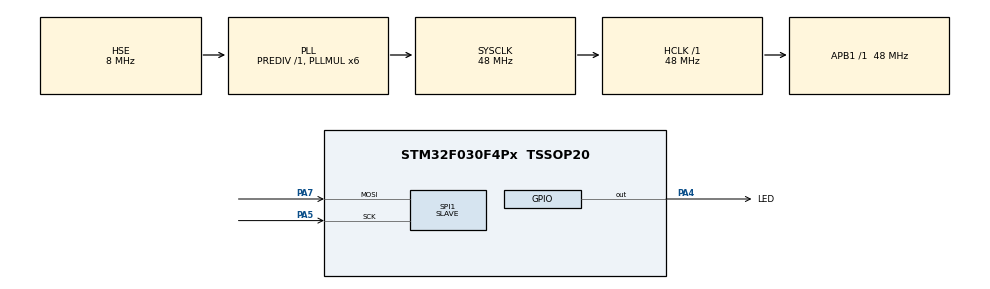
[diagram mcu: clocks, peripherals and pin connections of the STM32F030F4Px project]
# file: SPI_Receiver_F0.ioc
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Mcu.Family=STM32F0
Mcu.Name=STM32F030F4Px
Mcu.Package=TSSOP20
NVIC.SPI1_IRQn=true\:0\:0\:false\:false\:true\:true\:true
PA13.Mode=Serial_Wire
PA13.Signal=SYS_SWDIO
PA14.Mode=Serial_Wire
PA14.Signal=SYS_SWCLK
PA4.GPIO_Label=LED
PA4.Signal=GPIO_Output
PA5.Mode=RX_Only_Simplex_Unidirect_Slave
PA5.Signal=SPI1_SCK
PA7.Mode=RX_Only_Simplex_Unidirect_Slave
PA7.Signal=SPI1_MOSI
PF0-OSC_IN.Mode=HSE-External-Oscillator
PF0-OSC_IN.Signal=RCC_OSC_IN
PF1-OSC_OUT.Mode=HSE-External-Oscillator
PF1-OSC_OUT.Signal=RCC_OSC_OUT
ProjectManager.HeapSize=0x200
ProjectManager.StackSize=0x400
ProjectManager.TargetToolchain=STM32CubeIDE
RCC.AHBFreq_Value=48000000
RCC.APB1Freq_Value=48000000
RCC.APB1TimFreq_Value=48000000
RCC.HCLKFreq_Value=48000000
RCC.PLLMUL=RCC_PLL_MUL6
RCC.PLLSourceVirtual=RCC_PLLSOURCE_HSE
RCC.SYSCLKFreq_VALUE=48000000
RCC.SYSCLKSource=RCC_SYSCLKSOURCE_PLLCLK
SPI1.DataSize=SPI_DATASIZE_8BIT
SPI1.Direction=SPI_DIRECTION_2LINES_RXONLY
SPI1.Mode=SPI_MODE_SLAVE
SPI1.VirtualType=VM_SLAVE
board=custom

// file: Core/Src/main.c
/* USER CODE BEGIN Header */
/**
  ******************************************************************************
  * @file           : main.c
  * @brief          : Main program body
  ******************************************************************************
  * @attention
  *
  * <h2><center>&copy; Copyright (c) 2021 STMicroelectronics.
  * All rights reserved.</center></h2>
  *
  * This software component is licensed by ST under BSD 3-Clause license,
  * the "License"; You may not use this file except in compliance with the
  * License. You may obtain a copy of the License at:
  *                        opensource.org/licenses/BSD-3-Clause
  *
  ******************************************************************************
  */
/* USER CODE END Header */
#include "main.h"

SPI_HandleTypeDef hspi1;

void SystemClock_Config(void);
static void MX_GPIO_Init(void);
static void MX_SPI1_Init(void);

/* USER CODE BEGIN 0 */
void led_on()
{
  HAL_GPIO_WritePin(LED_GPIO_Port, LED_Pin, GPIO_PIN_RESET);
}

void led_off()
{
  HAL_GPIO_WritePin(LED_GPIO_Port, LED_Pin, GPIO_PIN_SET);
}

void led_toggle()
{
  HAL_GPIO_TogglePin(LED_GPIO_Port, LED_Pin);
}

long int count = 0;

void HAL_SPI_RxCpltCallback(SPI_HandleTypeDef *hspi)
{
  if(hspi == &hspi1)
  {
    // if(!hspi1.TxXferCount && !fl)
    // {
    //   fl=1;
    // }
//    led_toggle();
//    count++;
  }
  count++;
//  led_on();
  led_toggle();
}
/* USER CODE END 0 */

int main(void)
{

  /* MCU Configuration--------------------------------------------------------*/

  /* Reset of all peripherals, Initializes the Flash interface and the Systick. */
  HAL_Init();

  /* Configure the system clock */
  SystemClock_Config();

  /* Initialize all configured peripherals */
  MX_GPIO_Init();
  MX_SPI1_Init();
  /* USER CODE BEGIN 2 */
  led_on();
  HAL_Delay(2000);
  led_off();
  HAL_Delay(1000);

  uint8_t data_rx = 0;

  HAL_SPI_Receive_IT(&hspi1, &data_rx, sizeof(data_rx));
  /* USER CODE END 2 */

  /* Infinite loop */
  /* USER CODE BEGIN WHILE */
  while (1)
  {
	  HAL_Delay(5000);

	  HAL_Delay(1);
    /* USER CODE END WHILE */

  }
}

void SystemClock_Config(void)
{
  RCC_OscInitTypeDef RCC_OscInitStruct = {0};
  RCC_ClkInitTypeDef RCC_ClkInitStruct = {0};

  /** Initializes the RCC Oscillators according to the specified parameters
  * in the RCC_OscInitTypeDef structure.
  */
  RCC_OscInitStruct.OscillatorType = RCC_OSCILLATORTYPE_HSE;
  RCC_OscInitStruct.HSEState = RCC_HSE_ON;
  RCC_OscInitStruct.PLL.PLLState = RCC_PLL_ON;
  RCC_OscInitStruct.PLL.PLLSource = RCC_PLLSOURCE_HSE;
  RCC_OscInitStruct.PLL.PLLMUL = RCC_PLL_MUL6;
  RCC_OscInitStruct.PLL.PREDIV = RCC_PREDIV_DIV1;
  if (HAL_RCC_OscConfig(&RCC_OscInitStruct) != HAL_OK)
  {
    Error_Handler();
  }
  /** Initializes the CPU, AHB and APB buses clocks
  */
  RCC_ClkInitStruct.ClockType = RCC_CLOCKTYPE_HCLK|RCC_CLOCKTYPE_SYSCLK
                              |RCC_CLOCKTYPE_PCLK1;
  RCC_ClkInitStruct.SYSCLKSource = RCC_SYSCLKSOURCE_PLLCLK;
  RCC_ClkInitStruct.AHBCLKDivider = RCC_SYSCLK_DIV1;
  RCC_ClkInitStruct.APB1CLKDivider = RCC_HCLK_DIV1;

  if (HAL_RCC_ClockConfig(&RCC_ClkInitStruct, FLASH_LATENCY_1) != HAL_OK)
  {
    Error_Handler();
  }
}

static void MX_SPI1_Init(void)
{

  /* SPI1 parameter configuration*/
  hspi1.Instance = SPI1;
  hspi1.Init.Mode = SPI_MODE_SLAVE;
  hspi1.Init.Direction = SPI_DIRECTION_2LINES_RXONLY;
  hspi1.Init.DataSize = SPI_DATASIZE_8BIT;
  hspi1.Init.CLKPolarity = SPI_POLARITY_LOW;
  hspi1.Init.CLKPhase = SPI_PHASE_1EDGE;
  hspi1.Init.NSS = SPI_NSS_SOFT;
  hspi1.Init.FirstBit = SPI_FIRSTBIT_MSB;
  hspi1.Init.TIMode = SPI_TIMODE_DISABLE;
  hspi1.Init.CRCCalculation = SPI_CRCCALCULATION_DISABLE;
  hspi1.Init.CRCPolynomial = 7;
  hspi1.Init.CRCLength = SPI_CRC_LENGTH_DATASIZE;
  hspi1.Init.NSSPMode = SPI_NSS_PULSE_DISABLE;
  if (HAL_SPI_Init(&hspi1) != HAL_OK)
  {
    Error_Handler();
  }

}

static void MX_GPIO_Init(void)
{
  GPIO_InitTypeDef GPIO_InitStruct = {0};

  /* GPIO Ports Clock Enable */
  __HAL_RCC_GPIOF_CLK_ENABLE();
  __HAL_RCC_GPIOA_CLK_ENABLE();

  /*Configure GPIO pin Output Level */
  HAL_GPIO_WritePin(LED_GPIO_Port, LED_Pin, GPIO_PIN_RESET);

  /*Configure GPIO pin : LED_Pin */
  GPIO_InitStruct.Pin = LED_Pin;
  GPIO_InitStruct.Mode = GPIO_MODE_OUTPUT_PP;
  GPIO_InitStruct.Pull = GPIO_NOPULL;
  GPIO_InitStruct.Speed = GPIO_SPEED_FREQ_LOW;
  HAL_GPIO_Init(LED_GPIO_Port, &GPIO_InitStruct);

}

void Error_Handler(void)
{
  __disable_irq();
  while (1)
  {
  }
}

/************************ (C) COPYRIGHT STMicroelectronics *****END OF FILE****/
